# CY8C5868AXI_LP035 register map
File version: 0.1
CY8C58LP
Registers are 8-bit, read-write, no defined reset value unless marked. A register's access mark holds for its fields unless they carry their own. Offsets are from the block's base; lines under a group give offsets from that group; [hi:lo] are bit positions; {n}, {i} and the like mark numbered series; 'fields as' and 'values as' point back to an identical list; <NAME> marks a mode.

## Memory map
0x00000000 Display2 — UART
0x00000000 Display1 — UART
0x00000000 Timer_Tick
0x00000000 I2C_Bus
0x00000000 RF_Physical — UART
0x00000000 Timer_DispenserState
0x00000000 Dispenser — UART
0x00000000 Printer — UART
0x40006406 CRC_Security
0x40006462 StatusReg_iButton5thCRCBit
0x40006470 Clock_iButton
0x40006471 Reset_CRC
0x40006473 Reset_iButton
0x40006475 Input_iButton
0x40006574 Reset_DispenserTimer
0x40006577 Clock_CRC

## Display2 — UART
Base 0x00000000
0x4000642D RX_Display2_RX_ADDRESS1 — RX Address1 Register
0x4000643D RX_Display2_RX_ADDRESS2 — RX Address2 Register
0x4000644D RX_Display2_RX_DATA — RX Data Register
0x4000644F TX_Display2_TX_DATA — TX Data Register
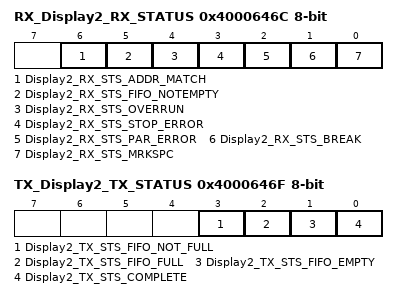
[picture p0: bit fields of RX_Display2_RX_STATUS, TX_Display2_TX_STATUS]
0x4000646C RX_Display2_RX_STATUS — RX status register
  [6] Display2_RX_STS_ADDR_MATCH ro, [5] Display2_RX_STS_FIFO_NOTEMPTY ro, [4] Display2_RX_STS_OVERRUN ro, [3] Display2_RX_STS_STOP_ERROR ro, [2] Display2_RX_STS_PAR_ERROR ro, [1] Display2_RX_STS_BREAK ro, [0] Display2_RX_STS_MRKSPC ro
0x4000646F TX_Display2_TX_STATUS — TX status register
  [3] Display2_TX_STS_FIFO_NOT_FULL ro, [2] Display2_TX_STS_FIFO_FULL ro, [1] Display2_TX_STS_FIFO_EMPTY ro, [0] Display2_TX_STS_COMPLETE ro

## Display1 — UART
Base 0x00000000
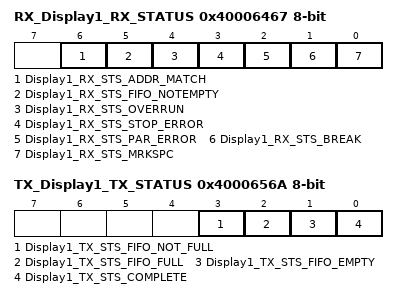
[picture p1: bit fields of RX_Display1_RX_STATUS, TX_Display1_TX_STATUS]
0x40006467 RX_Display1_RX_STATUS — RX status register
  [6] Display1_RX_STS_ADDR_MATCH ro, [5] Display1_RX_STS_FIFO_NOTEMPTY ro, [4] Display1_RX_STS_OVERRUN ro, [3] Display1_RX_STS_STOP_ERROR ro, [2] Display1_RX_STS_PAR_ERROR ro, [1] Display1_RX_STS_BREAK ro, [0] Display1_RX_STS_MRKSPC ro
0x40006527 RX_Display1_RX_ADDRESS1 — RX Address1 Register
0x40006537 RX_Display1_RX_ADDRESS2 — RX Address2 Register
0x40006547 RX_Display1_RX_DATA — RX Data Register
0x4000654A TX_Display1_TX_DATA — TX Data Register
0x4000656A TX_Display1_TX_STATUS — TX status register
  [3] Display1_TX_STS_FIFO_NOT_FULL ro, [2] Display1_TX_STS_FIFO_FULL ro, [1] Display1_TX_STS_FIFO_EMPTY ro, [0] Display1_TX_STS_COMPLETE ro

## Timer_Tick
Base 0x00000000
0x400043A3 Timer_Tick_GLOBAL_ENABLE — PM.ACT.CFG
  [3:0] en_timer — Enable timer/counters.
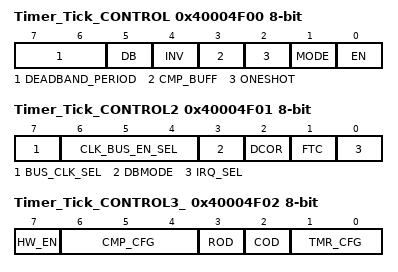
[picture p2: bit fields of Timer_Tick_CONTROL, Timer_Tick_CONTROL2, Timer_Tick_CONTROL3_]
0x40004F00 Timer_Tick_CONTROL — TMRx.CFG0
  [7:6] DEADBAND_PERIOD
  [5] DB — Deadband mode--Deadband phases phi1 and phi2 are outputted on CMP and TC output pins respectively.
    0=Timer (CMP and TC are output.); 1=Deadband (PHI1 (instead of CMP) and PHI2 (instead of TC) are output.)
  [4] INV — Invert sense of TIMEREN signal
  [3] CMP_BUFF — Buffer compare register. Compare register updates only on timer terminal count.
  [2] ONESHOT — Timer stops upon reaching stop condition defined by TMR_CFG bits. Can be restarted by asserting TIMER RESET or disabling and re-enabling block.
  [1] MODE — Mode. (0 = Timer; 1 = Comparator)
    0=Timer mode. CNT/CMP register holds timer count value.; 1=Comparator mode. CNT/CMP register holds comparator threshold value.
  [0] EN — Enables timer/comparator.
0x40004F01 Timer_Tick_CONTROL2 — TMRx.CFG1
  [7] BUS_CLK_SEL — Bus Clock selection.
  [6:4] CLK_BUS_EN_SEL — Digital Global Clock selection.
  [3] DBMODE — Deadband mode (asynchronous/synchronous). CMP output pin is also affected when not in deadband mode (CFG0.DEADBAND).
  [2] DCOR — Disable Clear on Read (DCOR) of Status Register SR0.
  [1] FTC — First Terminal Count (FTC). Setting this bit forces a single pulse on the TC pin when first enabled.
    0=Disable_FTC (Disable the single cycle pulse, which signifies the timer is starting.); 1=Enable_FTC (Enable the single cycle pulse, which signifies the timer is starting.)
  [0] IRQ_SEL — Irq selection. (0 = raw interrupts; 1 = status register interrupts)
0x40004F02 Timer_Tick_CONTROL3_ — TMRx.CFG2
  [7] HW_EN — When set Timer Enable controls counting.
  [6:4] CMP_CFG — Comparator configurations
    0=Equal (Compare Equal); 1=Less_than (Compare Less Than); 2=Less_than_or_equal (Compare Less Than or Equal .); 3=Greater (Compare Greater Than .); 4=Greater_than_or_equal (Compare Greater Than or Equal)
  [3] ROD — Reset On Disable (ROD). Resets internal state of output logic
  [2] COD — Clear On Disable (COD). Clears or gates outputs to zero.
  [1:0] TMR_CFG — Timer configuration (MODE = 0): 000 = Continuous; 001 = Pulsewidth; 010 = Period; 011 = Stop on IRQ
    0=Continuous (Timer runs while EN bit of CFG0 register is set to '1'.); 1=Pulsewidth (Timer runs from positive to negative edge of TIMEREN.); 2=Period (Timer runs from positive to positive edge of TIMEREN.); 3=Irq (Timer runs until IRQ.)
0x40004F04 Timer_Tick_PERIOD 16-bit — TMRx.PER0 - Assigned Period
0x40004F06 Timer_Tick_COUNTER 16-bit — TMRx.CNT_CMP0 - Current Down Counter Value
